# AT32F415 register map
Vendor: Keil; Series: AT32F415; File version: 1.0
CPU: CM4 r0p1, little endian, no MPU, FPU, 4 interrupt priority bits
Registers are 32-bit, read-write, reset 0x0 unless marked. A register's access mark holds for its fields unless they carry their own. Offsets are from the block's base; [hi:lo] are bit positions; {n}, {i} and the like mark numbered series; 'fields as' and 'values as' point back to an identical list.

## IOMUX — IO MUX function
Base 0x40010000
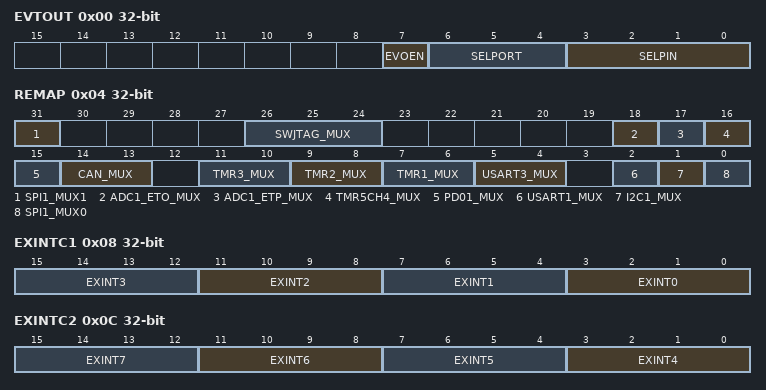
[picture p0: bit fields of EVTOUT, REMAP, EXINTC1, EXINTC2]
0x00 EVTOUT — Event output register (IOMUX_EVTOUT)
  [7] EVOEN — Event output enable
    0=Disable; 1=Enable
  [6:4] SELPORT — Select port
    0=GPIOA; 1=GPIOB; 2=GPIOC; 3=GPIOD; 6=GPIOF
  [3:0] SELPIN — Select pin
0x04 REMAP — IO MUX remap register
  [31] SPI1_MUX1 — SPI1 muxing bit1
    0=MUX0 (CS/PA4, SCK/PA5, MISO/PA6, MOSI/PA7, MCK/PB0); 1=MUX1 (CS/PA15, SCK/PB3, MISO/PB4, MOSI/PB5,MCK/PB6)
  [26:24] SWJTAG_MUX — SWD JTAG muxing
    0=SWDandJTAG (Supports SWD and JTAG. All SWJTAG pins cannot be used as GPIOs); 1=SWDandJTAGwithoutNJTRST (Supports SWD and JTAG. NJTRST is disabled. PB4 can be used as GPIO); 2=SWD (Supports SWD but JTAG is disabled. PA15/PB3/PB4 can be used as GPIOs); 4=Disable (SWD and JTAG are disabled. All SWJTAG pins can be used as GPIOs)
  [18] ADC1_ETO_MUX — ADC1 external trigger ordinary conversion muxing
    0=EXINT11 (ADC1 external trigger ordinary conversion is connected to EXINT11); 1=TMR1_TRGO (ADC1 external trigger ordinary conversion TMR1_TRGO)
  [17] ADC1_ETP_MUX — ADC1 external trigger preempted conversion muxing
    0=EXINT15 (ADC1 external trigger preempted conversion is connected to EXINT15); 1=TMR1CH4 (ADC1 external trigger preempted conversion is connected to TMR1 channel 4)
  [16] TMR5CH4_MUX — TMR5 channel4 internal muxing
    0=PA3 (TMR5_CH4 is connected to PA3); 1=LICK (TMR5_CH4 is connected to LICK. LICK can be calibrated)
  [15] PD01_MUX — PD0/PD1 muxing on OSCIN/OSCOUT
    0=MUX0 (Not PD0 and PD1 mapping); 1=HEXT (PD0 is mapped to HEXT_IN, while PD1 to HEXT_OUT)
  [14:13] CAN_MUX — CAN1 muxing
    0=MUX0 (RX/PA11, TX/PA12); 2=MUX2 (RX/PB8, TX/PB9)
  [11:10] TMR3_MUX — TMR3 muxing
    0=MUX0 (CH1/PA6, CH2/PA7, CH3/PB0 and CH4/PB1); 2=MUX2 (CH1/EXT/PA0, CH2/PA1, CH3/PB10, CH4/PB11); 3=MUX3 (CH1/EXT/PA15, CH2/PB3, CH3/PB10, CH4/PB11)
  [9:8] TMR2_MUX — TMR2 muxing
    0=MUX0 (CH1/EXT/PA0, CH2/PA1, CH3/PA2, CH4/PA3); 1=MUX1 (CH1/EXT/PA15, CH2/PB3, CH3/PA2, CH4/PA3); 2=MUX2 (CH1/EXT/PA0, CH2/PA1, CH3/PB10, CH4/PB11); 3=MUX3 (CH1/EXT/PA15, CH2/PB3, CH3/PB10, CH4/PB11)
  [7:6] TMR1_MUX — TMR1 muxing
    0=MUX0 (EXT/PA12, CH1/PA8, CH2/PA9, CH3/PA10, CH4/PA11, BRK/PB12, CH1C/PB13, CH2C/PB14, CH3C/PB15); 1=MUX1 (EXT/PA12, CH1/PA8, CH2/PA9, CH3/PA10, CH4/PA11, BRK/PA6, CH1C/PA7, CH2C/PB0, CH3C/PB1)
  [5:4] USART3_MUX — USART3 muxing
    0=MUX0 (TX/PB10, RX/PB11, CK/PB12, CTS/PB13, RTS/PB14); 1=MUX1 (TX/PC10, RX/PC11, CK/PC12, CTS/PB13, RTS/PB14); 2=MUX2 (TX/PA7, RX/PA6, CK/PA5, CTS/PB1, RTS/PB0)
  [2] USART1_MUX — USART1 muxing
    0=MUX0 (TX/PA9, RX/PA10); 1=MUX1 (TX/PB6, RX/PB7)
  [1] I2C1_MUX — I2C1 muxing
    0=MUX0 (SCL/PB6, SDA/PB7 SMBA/PB5); 1=MUX1 (SCL/PB8, SDA/PB9 SMBA/PB5)
  [0] SPI1_MUX0 range 0..0 — SPI1 muxing bit0
0x08 EXINTC1 — External interrupt configuration register 1 (IOMUX_EXINTC1)
  [4n+3:4n] EXINT{n} (n=0..3) — Select the input source for EXINT{n} external interrupt
    0=GPIOA (GPIOA pin); 1=GPIOB (GPIOB pin); 2=GPIOC (GPIOB pin); 3=GPIOD (GPIOB pin); 4=GPIOF (GPIOB pin)
0x0C EXINTC2 — External interrupt configuration register 2 (IOMUX_EXINTC2)
  [4n-13:4n-16] EXINT{n} (n=4..7) — Select the input source for EXINT{n} external interrupt
    values as EXINTC1.EXINT0
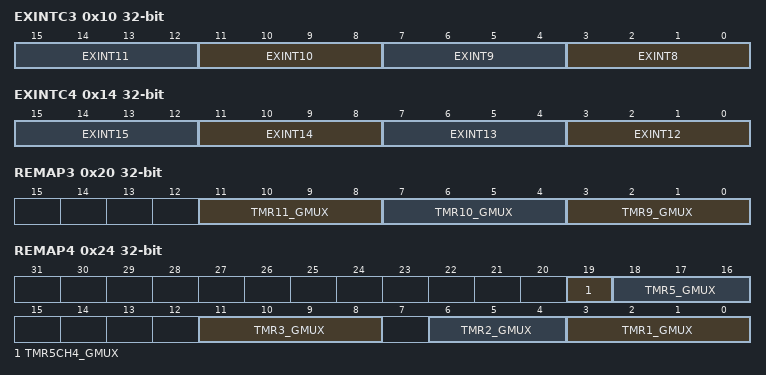
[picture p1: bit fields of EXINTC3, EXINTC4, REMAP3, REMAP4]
0x10 EXINTC3 — External interrupt configuration register 3 (IOMUX_EXINTC3)
  [4n-29:4n-32] EXINT{n} (n=8..11) — Select the input source for EXINT{n} external interrupt
    values as EXINTC1.EXINT0
0x14 EXINTC4 — External interrupt configuration register 4 (IOMUX_EXINTC4)
  [4n-45:4n-48] EXINT{n} (n=12..15) — Select the input source for EXINT{n} external interrupt
    values as EXINTC1.EXINT0
0x1C REMAP2 wo — IO MUX remap register 2
  [27:26] CMP_MUX — CMP internal muxing
    0=MUX0 (CMP1_OUT is connected to PA0, CMP2_OUT is connected to PA2); 1=MUX1 (CMP1_OUT is connected to PA6, CMP2_OUT is connected to PA7); 2=MUX2 (CMP1_OUT is connected to PA11, CMP2_OUT is connected to PA12;)
0x20 REMAP3 — IO MUX remap register 3
  [11:8] TMR11_GMUX — TMR11 muxing
    0=MUX0 (CH1/PB9); 2=MUX1 (CH1/PA7)
  [7:4] TMR10_GMUX — TMR10 muxing
    0=MUX0 (CH1/PB8); 2=MUX1 (CH1/PA6)
  [3:0] TMR9_GMUX — TMR9 muxing
    0=MUX0 (CH1/PA2, CH2/PA3); 2=MUX1 (CH1/PB14, CH2/PB15)
0x24 REMAP4 — IO MUX remap register 4
  [19] TMR5CH4_GMUX — TMR5CH4 muxing
    0=PA3 (TMR5_CH4 is connected to PA3); 1=LICK (LICK is connected to TMR5_CH4 to get calibration)
  [18:16] TMR5_GMUX — TMR5 muxing
    0=MUX0 (CH1/PA0 CH2/PA1 CH3/PA2 CH4/PA3); 1=MUX1 (CH1/PF4 CH2/PF5 CH3/PA2 CH4/PA3)
  [11:8] TMR3_GMUX — TMR3 muxing
    0=MUX0 (CH1/PA6 CH2/PA7 CH3/PB0 CH4/PB1); 1=MUX1 (CH1/PB4 CH2/PB5 CH3/PB0 CH4/PB1)
  [6:4] TMR2_GMUX — TMR2 muxing
    0=MUX0 (CH1_EXT/PA0 CH2/PA1 CH3/PA2 CH4/PA3); 1=MUX1 (CH1_EXT/PA15 CH2/PB3 CH3/PA2 CH4/PA3); 2=MUX2 (CH1_EXT/PA0 CH2/PA1 CH3/PB10 CH4/PB11); 3=MUX3 (CH1_EXT/PA15 CH2/PB3 CH3/PB10 CH4/PB11)
  [3:0] TMR1_GMUX — TMR1 muxing
    0=MUX0 (EXT/PA12, CH1/PA8, CH2/PA9, CH3/PA10, CH4/PA11, BRK/PB12, CH1C/PB13, CH2C/PB14, CH3C/PB15); 1=MUX1 (EXT/PA12, CH1/PA8, CH2/PA9, CH3/PA10, CH4/PA11, BRK/PA6, CH1C/PA7, CH2C/PB0, CH3C/PB1); 2=MUX2 (EXT/PA0, CH1/PC6, CH2/PC7, CH3/PC8, CH4/PC9, BRK/PA6, CH1C/PA7, CH2C/PB0, CH3C/PB1)
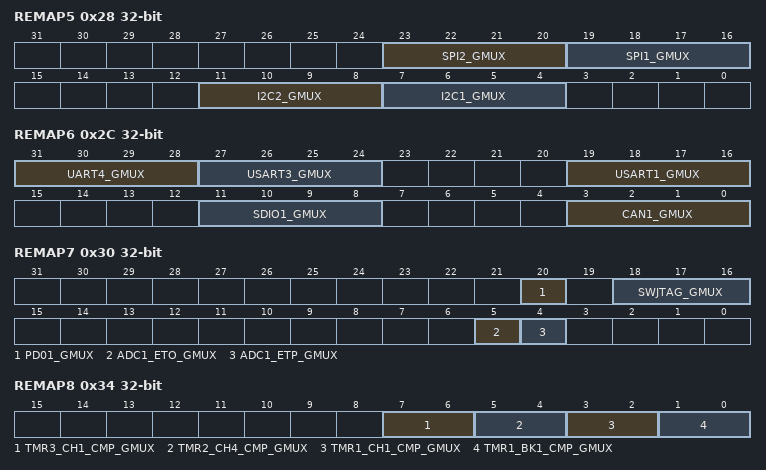
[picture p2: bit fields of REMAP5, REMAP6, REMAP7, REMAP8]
0x28 REMAP5 — IO MUX remap register 5
  [23:20] SPI2_GMUX — SPI2 muxing
    0=MUX0 (CS/PB12, SCK/PB13, MISO/PB14, MOSI/PB15, MCK/PC6); 1=MUX1 (CS/PA15, SCK/PB3, MISO/PB4, MOSI/PB5, MCK/PC7)
  [19:16] SPI1_GMUX — SPI1 muxing
    0=MUX0 (CS/PA4, SCK/PA5, MISO/PA6, MOSI/PA7, MCK/PB0); 1=MUX1 (CS/PA15, SCK/PB3, MISO/PB4, MOSI/PB5, MCK/PB6)
  [11:8] I2C2_GMUX — I2C2 muxing
    0=MUX0 (SCL/PB10, SDA/PB11, SMBA/PB12); 1=MUX1 (SCL/PA8, SDA/PC9, SMBA/PA9); 2=MUX2 (SCL/PA8, SDA/PB4, SMBA/PA9); 3=MUX3 (SCL/PF6, SDA/PF7, SMBA/PA9)
  [7:4] I2C1_GMUX — I2C1 muxing
    0=MUX0 (SCL/PB6, SDA/PB7, SMBA/PB5); 1=MUX1 (SCL/PB8, SDA/PB9, SMBA/PB5); 2=MUX2 (SCL/PF6, SDA/PF7, SMBA/PB5)
0x2C REMAP6 — IO MUX remap register 6
  [31:28] UART4_GMUX — UART4 muxing
    0=MUX0 (TX/PC10 RX/PC11); 1=MUX1 (TX/PF4 RX/PF5)
  [27:24] USART3_GMUX — USART3 muxing
    0=MUX0 (TX/PB10, RX/PB11, CK/PB12, CTS/PB13, RTS/PB14); 1=MUX1 (TX/PC10, RX/PC11, CK/PC12, CTS/PB13, RTS/PB14); 2=MUX2 (TX/PA7, RX/PA6, CK/PA5, CTS/PB1 RTS/PB0)
  [19:16] USART1_GMUX — USART1 muxing
    0=MUX0 (TX/PA9, RX/PA10); 1=MUX1 (TX/PB6, RX/PB7)
  [11:8] SDIO1_GMUX — SDIO1 muxing
    0=MUX0 (D0/PC8, D1/PC9, D2/PC10, D3/PC11, D4/PB8, D5/PB9, D6/PC6, D7/PC7, CK/PC12, CMD/PD2); 4=MUX1 (D0/PC0, D1/PC1, D2/PC2, D3/PC3, D4/PA4, D5/PA5, D6/PA6, D7/PA7, CK/PC4, CMD/PC5); 5=MUX2 (D0/PA4, D1/PA5, D2/PA6, D3/PA7, CK/PC4, CMD/PC5); 6=MUX3 (D0/PC0, D1/PC1, D2/PC2, D3/PC3, D4/PA4, D5/PA5, D6/PA6, D7/PA7, CK/PA2, CMD/PA3); 7=MUX4 (D0/PA4, D1/PA5, D2/PA6, D3/PA7, CK/PA2, CMD/PA3)
  [3:0] CAN1_GMUX — CAN1 muxing
    0=MUX0 (RX/PA11, TX/PA12); 2=MUX1 (RX/PB8, TX/PB9)
0x30 REMAP7 — IO MUX remap register 7
  [20] PD01_GMUX — PortD0/PortD1 muxing on OSC_IN/OSC_OUT
    values as REMAP.PD01_MUX
  [18:16] SWJTAG_GMUX — Serial wire JTAG muxing
    values as REMAP.SWJTAG_MUX
  [5] ADC1_ETO_GMUX — ADC1 external trigger ordinary conversion muxing
    values as REMAP.ADC1_ETO_MUX
  [4] ADC1_ETP_GMUX — ADC1 external trigger preempted conversion muxing
    values as REMAP.ADC1_ETP_MUX
0x34 REMAP8 — IO MUX remap register 8
  [7:6] TMR3_CH1_CMP_GMUX — TMR3 CH1 CMP muxing
    0=MUX0 (TMR3_GMUX IO signal is connected to TMR3 channel 1); 1=MUX1 (TMR3_GMUX IO signal is connected to TMR3 channel 1); 2=MUX2 (CMP output signal is connected to TMR3 channel 1); 3=MUX3 (Either CMP output signal or TMR3_GMUX IO signal is connected to TMR3 channel 1)
  [5:4] TMR2_CH4_CMP_GMUX — TMR2 CH4 CMP muxing
    0=MUX0 (TMR2_GMUX IO signal is connected to TMR2 channel 4); 1=MUX1 (TMR2_GMUX IO signal is connected to TMR2 channel 4); 2=MUX2 (CMP output signal is connected to TMR2 channel 4); 3=MUX3 (Either CMP output signal or TMR1_GMUX IO signal is connected to TMR2 channel 4)
  [3:2] TMR1_CH1_CMP_GMUX — TMR1 CH1 CMP muxing
    0=MUX0 (TMR1_GMUX IO signal is connected to TMR1 channel 1); 1=MUX1 (TMR1_GMUX IO signal is connected to TMR1 channel 1); 2=MUX2 (CMP output signal is connected to TMR1 channel 1); 3=MUX3 (Either CMP output signal or TMR1_GMUX IO signal is connected to TMR1 channel 1)
  [1:0] TMR1_BK1_CMP_GMUX — TMR1 BK1 CMP muxing
    0=MUX0 (TMR1_GMUX IO signal is connected to TMR1 break channel 1); 1=MUX1 (TMR1_GMUX IO signal is connected to TMR1 break channel 1); 2=MUX2 (CMP output signal is connected to TMR1 break channel 1); 3=MUX3 (Either CMP output signal or TMR1_GMUX IO signal is connected to TMR1 break channel 1)
